# SAM9X60 device description
Architecture: ARM926EJS; Family: SAM9; Series: SAM9X
Registers are 32-bit, read-write, no defined reset value unless marked. A register's access mark holds for its fields unless they carry their own. Offsets are from the block's base; [hi:lo] are bit positions; {n}, {i} and the like mark numbered series.

## TDES — Triple Data Encryption Standard
Instances: TDES 0xF0038000
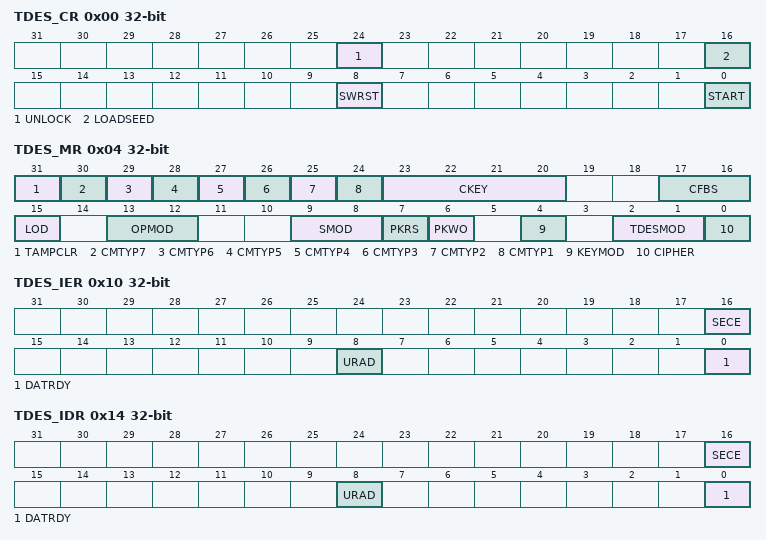
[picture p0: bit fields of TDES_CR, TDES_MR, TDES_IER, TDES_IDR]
0x00 TDES_CR wo — Control Register
  [24] UNLOCK — Unlock Processing
  [16] LOADSEED
  [8] SWRST — Software Reset
  [0] START — Start Processing
0x04 TDES_MR — Mode Register
  [31] TAMPCLR — Tamper Pin Clear Key Enable
  [30] CMTYP7 — Countermeasure Type 7
    0=NO_STARTDELAY (Countermeasure type 7 is disabled.); 1=STARTDELAY (Countermeasure type 7 is enabled.)
  [29] CMTYP6 — Countermeasure Type 6
    0=NO_UNIFORM (Countermeasure type 6 is disabled.); 1=UNIFORM (Countermeasure type 6 is enabled.)
  [28] CMTYP5 — Countermeasure Type 5
    0=NO_ADDACCESS (Countermeasure type 5 is disabled.); 1=ADDACCESS (Countermeasure type 5 is enabled.)
  [27] CMTYP4 — Countermeasure Type 4
    0=NO_IDLECURRENT (Countermeasure type 4 is disabled.); 1=IDLECURRENT (Countermeasure type 4 is enabled.)
  [26] CMTYP3 — Countermeasure Type 3
    0=NO_RESTART (Countermeasure type 3 is disabled.); 1=RESTART (Countermeasure type 3 is enabled.)
  [25] CMTYP2 — Countermeasure Type 2
    0=NO_DUMMY (Countermeasure type 2 is disabled.); 1=DUMMY (Countermeasure type 2 is enabled.)
  [24] CMTYP1 — Countermeasure Type 1
    0=NO_PAUSE (Countermeasure type 1 is disabled.); 1=PAUSE (Countermeasure type 1 is enabled.)
  [23:20] CKEY — Countermeasure Key
  [17:16] CFBS — Cipher Feedback Data Size
    0=SIZE_64BIT (64-bit); 1=SIZE_32BIT (32-bit); 2=SIZE_16BIT (16-bit); 3=SIZE_8BIT (8-bit)
  [15] LOD — Last Output Data Mode
  [13:12] OPMOD — Operating Mode
    0=ECB (Electronic Code Book mode); 1=CBC (Cipher Block Chaining mode); 2=OFB (Output Feedback mode); 3=CFB (Cipher Feedback mode)
  [9:8] SMOD — Start Mode
    0=MANUAL_START (Manual Mode); 1=AUTO_START (Auto Mode); 2=IDATAR0_START (TDES_IDATAR0 accesses only Auto Mode)
  [7] PKRS — Private Key Internal Register Select
  [6] PKWO — Private Key Write Once
  [4] KEYMOD — Key Mode
  [2:1] TDESMOD — ALGORITHM Mode
    0=SINGLE_DES (Single DES processing using Key 1 Registers); 1=TRIPLE_DES (Triple DES processing using Key 1, Key 2 and Key 3 Registers); 2=XTEA (XTEA processing using Key 1 and Key 2 Registers)
  [0] CIPHER — Processing Mode
    0=DECRYPT (Decrypts data.); 1=ENCRYPT (Encrypts data.)
0x10 TDES_IER wo — Interrupt Enable Register
  [16] SECE — Security and/or Safety Event Interrupt Enable
  [8] URAD — Unspecified Register Access Detection Interrupt Enable
  [0] DATRDY — Data Ready Interrupt Enable
0x14 TDES_IDR wo — Interrupt Disable Register
  [16] SECE — Security and/or Safety Event Interrupt Disable
  [8] URAD — Unspecified Register Access Detection Interrupt Disable
  [0] DATRDY — Data Ready Interrupt Disable
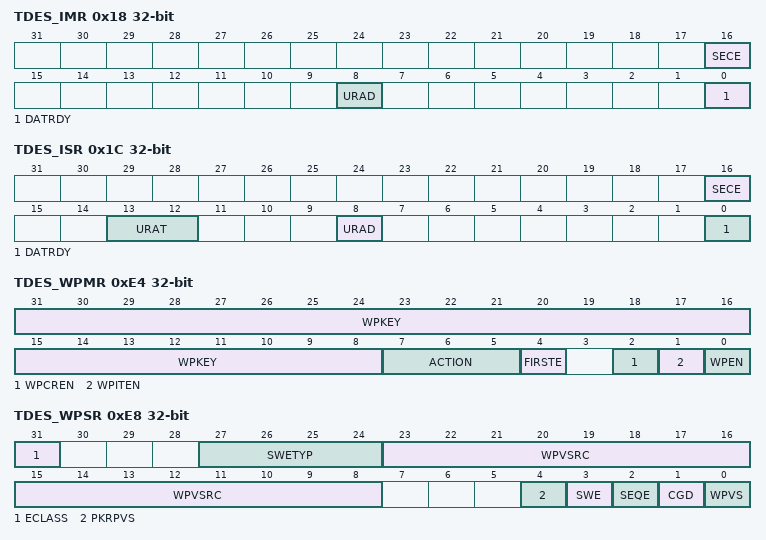
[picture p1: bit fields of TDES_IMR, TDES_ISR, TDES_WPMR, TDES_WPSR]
0x18 TDES_IMR ro — Interrupt Mask Register
  [16] SECE — Security and/or Safety Event Interrupt Mask
  [8] URAD — Unspecified Register Access Detection Interrupt Mask
  [0] DATRDY — Data Ready Interrupt Mask
0x1C TDES_ISR ro — Interrupt Status Register
  [16] SECE — Security and/or Safety Event Interrupt Mask
  [13:12] URAT — Unspecified Register Access (cleared by setting bit TDES_CR.SWRST)
    0=IDR_WR_PROCESSING (Input Data Register written during data processing when SMOD = 0x2 mode.); 1=ODR_RD_PROCESSING (Output Data Register read during data processing.); 2=MR_WR_PROCESSING (Mode Register written during data processing.); 3=WOR_RD_ACCESS (Write-only register read access.)
  [8] URAD — Unspecified Register Access Detection Status (cleared by setting bit TDES_CR.SWRST)
  [0] DATRDY — Data Ready (cleared by setting bit START or bit SWRST in TDES_CR or by reading TDES_ODATARx)
{0x20+4i} TDES_KEY1WR[{i}] (i=0..1) wo — Key 1 Word Register
  [31:0] KEY1W — Key 1 Word
{0x28+4i} TDES_KEY2WR[{i}] (i=0..1) wo — Key 2 Word Register
  [31:0] KEY2W — Key 2 Word
{0x30+4i} TDES_KEY3WR[{i}] (i=0..1) wo — Key 3 Word Register
  [31:0] KEY3W — Key 3 Word
{0x40+4i} TDES_IDATAR[{i}] (i=0..1) wo — Input Data Register
  [31:0] IDATA — Input Data
{0x50+4i} TDES_ODATAR[{i}] (i=0..1) ro — Output Data Register
  [31:0] ODATA — Output Data
{0x60+4i} TDES_IVR[{i}] (i=0..1) wo — Initialization Vector Register
  [31:0] IV — Initialization Vector
0x70 TDES_XTEA_RNDR — XTEA Rounds Register
  [5:0] XTEA_RNDS — Number of Rounds
0xE4 TDES_WPMR — Write Protection Mode Register
  [31:8] WPKEY — Write Protection Key
    0x444553=PASSWD (Writing any other value in this field aborts the write operation of bits WPEN, WPITEN and WPCREN. Always reads as 0.)
  [7:5] ACTION — Action on Abnormal Event Detection
    0=REPORT_ONLY (No action (stop or clear key) is performed when one of PKRPVS, WPVS, CGD, SEQE, or SWE flags are set.); 1=LOCK_PKRPVS_WPVS_SWE (If a processing is in progress when the TDES_WPSR.PKRPVS/WPVS/SWE event detection occurs, the current processing is ended normally but no other processing is started while a TDES_CR.UNLOCK command is issued.); 2=LOCK_CGD_SEQE (If a processing is in progress when the TDES_WPSR.CGD/SEQE event detection occurs, the current processing is ended normally but no other processing is started while a TDES_CR.UNLOCK command is issued.); 3=LOCK_ANY_EV (If a processing is in progress when the TDES_WPSR.PKRPVS/WPVS/CGD/SEQE/SWE events detection occurs, the current processing is ended normally but no other processing is started while a TDES_CR.UNLOCK command is issued.); 4=CLEAR_PKRPVS_WPVS_SWE (If a processing is in progress when the TDES_WPSR.PKRPVS/WPVS/SWE events detection occurs, the current processing is ended normally but no other processing is started while a TDES_CR.UNLOCK command is issued. Moreover, the TDES_KEYxWRx Key Word Registers are immediately cleared.); 5=CLEAR_CGD_SEQE (If a processing is in progress when the TDES_WPSR.CGD/SEQE events detection occurs, the current processing is ended normally but no other processing is started while a TDES_CR.UNLOCK command is issued. Moreover, the TDES_KEYxWRx Key Word Registers are immediately cleared.); 6=CLEAR_ANY_EV (If a processing is in progress when the TDES_WPSR.PKRPVS/WPVS/CGD/SEQE/SWE events detection occurs, the current processing is ended normally but no other processing is started while a TDES_CR.UNLOCK command is issued. Moreover, the TDES_KEYxWRx Key Word Registers are immediately cleared.)
  [4] FIRSTE — First Error Report Enable
  [2] WPCREN — Write Protection Control Enable
  [1] WPITEN — Write Protection Interrupt Enable
  [0] WPEN — Write Protection Enable
0xE8 TDES_WPSR ro — Write Protection Status Register
  [31] ECLASS — Software Error Class (cleared on read)
    0=WARNING (An abnormal access that does not affect system functionality.); 1=ERROR
  [27:24] SWETYP — Software Error Type (cleared on read)
    0=READ_WO (A write-only register has been read (Warning).); 1=WRITE_RO (TDES is enabled and a write access has been performed on a read-only register (Warning).); 2=UNDEF_RW (Access to an undefined address (Warning).); 3=CTRL_START (Abnormal use of TDES_CR.START command when DMA access is configured.); 4=WEIRD_ACTION (A key write, init value write, output data read, Mode register write, Private Key Bus access or XTEA round register has been performed while a current processing is in progress (abnormal).); 5=INCOMPLETE_KEY (A tentative of start is required while the keys are not fully loaded into the TDES_KEYxWRx registers.)
  [23:8] WPVSRC — Write Protection Violation Source (cleared on read)
  [4] PKRPVS — Private Key Register Protection Violation Status (cleared on read)
  [3] SWE — Software Control Error (cleared on read)
  [2] SEQE — Internal Sequencer Error (cleared on read)
  [1] CGD — Clock Glitch Detected (cleared on read)
  [0] WPVS — Write Protection Violation Status (cleared on read)
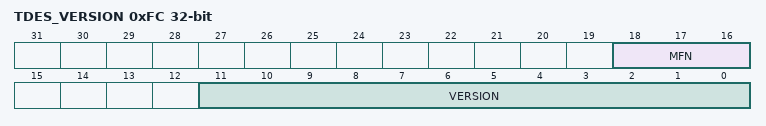
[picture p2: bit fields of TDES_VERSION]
0xFC TDES_VERSION ro — Version Register
  [18:16] MFN — Metal Fix Number
  [11:0] VERSION — Version of the Hardware Module
